AUTOSAR XML (schema 00050)
package /VectorAutosarExplorerGeneratedObjects/SYSTEM
  system System
    system mapping System_MPPNG
      data-mappings:
        data-element=PpFault.DeFault, system-signal=Signal_Fan_Fault_f777c54e31a89d5c
        data-element=PpSpeed.DeSpeed, system-signal=Signal_Fan_Setpoint_7226b1dfc825beac
        data-element=PpOBDdrivingCycle.DeOBDdrivingCycle, system-signal=Signal_Comfort_DrivingCycle_d5cecd98dc1c368d
    root-software-compositions:
      root sw composition prototype EcuSwComposition: software-composition=ECU_Composition
package /ECUCompositionTypes
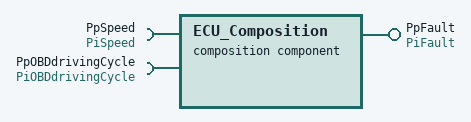
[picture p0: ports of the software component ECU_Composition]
  composition sw component type ECU_Composition
    provide port PpFault: nonqueued-sender-com-spec{data-element=DeFault, init-value=0}, provided-interface=PiFault
    require port PpSpeed: nonqueued-receiver-com-spec{data-element=DeSpeed, filter=data-filter-type=ALWAYS, init-value=0}, required-interface=PiSpeed
    require port PpOBDdrivingCycle: nonqueued-receiver-com-spec{data-element=DeOBDdrivingCycle, init-value=1}, required-interface=PiOBDdrivingCycle
    component CpCddIoHwAb: type=CtCddIoHwAb
    component CpApController: type=CtApController
    connect CpCddIoHwAb.PpPwmDcIoHwAb -> CpApController.PpPwmDcIoHwAb
    connect CpCddIoHwAb.PpPwmDeInitIoHwAb -> CpApController.PpPwmDeInitIoHwAb
    connect CpCddIoHwAb.PpPwmInitIoHwAb -> CpApController.PpPwmInitIoHwAb
    connect CpCddIoHwAb.PpAdcReadIoHwAb -> CpApController.PpAdcReadIoHwAb
    delegate CpApController.PpFault <-> outer port PpFault
    delegate CpApController.PpSpeed <-> outer port PpSpeed
    delegate CpApController.PpOBDdrivingCycle <-> outer port PpOBDdrivingCycle
package /EndToEndProtections
  end to end protection set EndToEndProtectionSet
